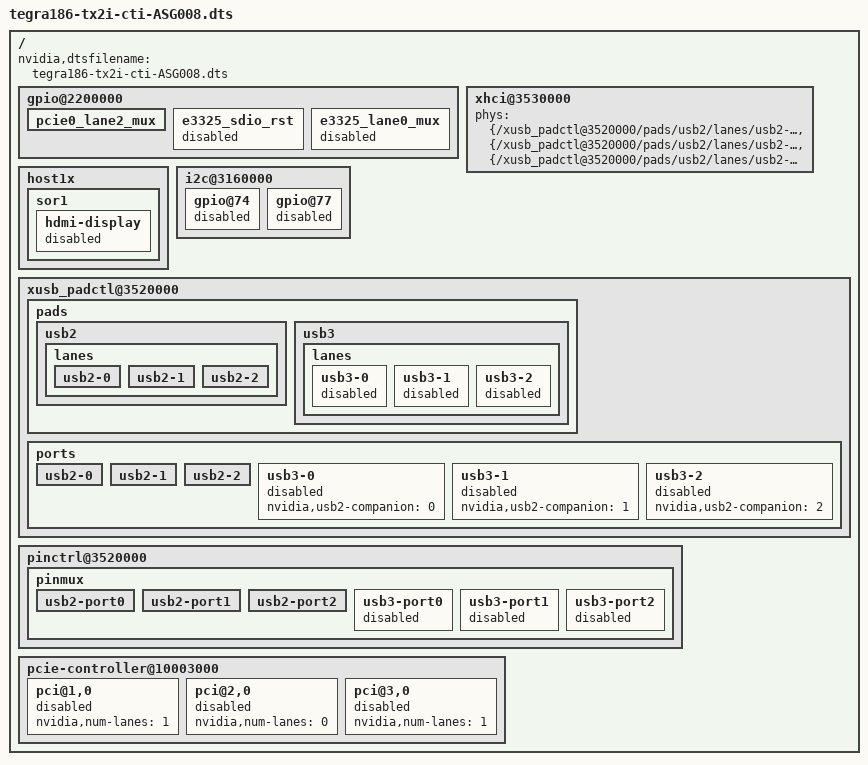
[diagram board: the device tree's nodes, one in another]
#include "tegra186-tx2i-cti-base.dts"

/{
    nvidia,dtsfilename = "tegra186-tx2i-cti-ASG008.dts";

    gpio@2200000 {
    /*enable this to enabled PCIe Controller #2*/
        pcie0_lane2_mux {
             status = "okay";
        };
    /******************************************/
    /*enable these two to enable USB3 Port 0*/
        e3325_sdio_rst {
           status = "disabled";
        };
        e3325_lane0_mux {
            status = "disabled";
        };
    /******************************************/

    };



    xhci@3530000 {
        status = "okay";
        phys = <&{/xusb_padctl@3520000/pads/usb2/lanes/usb2-0}>,
            <&{/xusb_padctl@3520000/pads/usb2/lanes/usb2-1}>,
            <&{/xusb_padctl@3520000/pads/usb2/lanes/usb2-2}>;
        phy-names = "usb2-0", "usb2-1", "usb2-2";
    };

    /*Disable HDMI out for sprocket*/
    host1x{
        sor1 {
            status = "okay";    //leave this enabled
            hdmi-display {
                status = "disabled";
            };
        };
    };


    i2c@3160000 {

        gpio@74{
            status = "disabled";


        };
        gpio@77{
            status = "disabled";

        };

    };


   xusb_padctl@3520000 {
        pads {
            usb2 {
                lanes {
                    usb2-0 {
                        status = "okay";
                    };
                    usb2-1 {
                        status = "okay";
                    };
                    usb2-2 {
                        status = "okay";
                    };
                };
            };
            usb3 {
                lanes {
                    usb3-0 {
                        status = "disabled";
                    };
                    usb3-1 {
                        status = "disabled";
                    };
                    usb3-2 {
                        status = "disabled";
                    };
                };
            };
        };
        ports {
            usb2-0 {
                status = "okay";
            };
            usb2-1 {
                status = "okay";
            };

            usb2-2 {
                status = "okay";
            };

            usb3-0 {
                nvidia,usb2-companion = <0>;
                status = "disabled";
            };
            usb3-1 {
                nvidia,usb2-companion = <1>;
                status = "disabled";
            };
            usb3-2 {
                nvidia,usb2-companion = <2>;
                status = "disabled";
            };
        };
    };
    pinctrl@3520000 {
        status = "okay";
           pinmux {
            usb2-port0 {
                status = "okay";
            };
            usb2-port1 {
                status = "okay";
            };

            usb2-port2 {
                status = "okay";
            };

            usb3-port0 {
                status = "disabled";
            };

            usb3-port1 {
                status = "disabled";
            };

            usb3-port2 {
                status = "disabled";
            };
        };
    };
    pcie-controller@10003000 {
        pci@1,0 {
            nvidia,num-lanes = <1>;
            status = "disabled";
        };
        pci@2,0 {
            nvidia,num-lanes = <0>;
            status = "disabled";
        };
        pci@3,0 {
            nvidia,num-lanes = <1>;
            status = "disabled";
        };
    };


};
